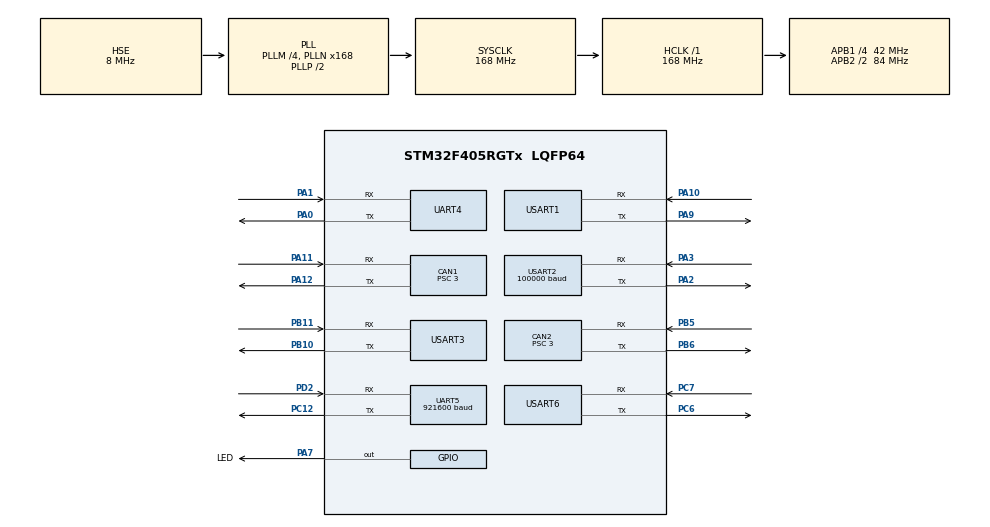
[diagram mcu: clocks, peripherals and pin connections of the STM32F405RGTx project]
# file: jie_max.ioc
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CAN1.ABOM=ENABLE
CAN1.BS1=CAN_BS1_6TQ
CAN1.BS2=CAN_BS2_7TQ
CAN1.CalculateBaudRate=1000000
CAN1.CalculateTimeBit=1000
CAN1.CalculateTimeQuantum=71.42857142857143
CAN1.NART=ENABLE
CAN1.Prescaler=3
CAN2.ABOM=ENABLE
CAN2.BS1=CAN_BS1_6TQ
CAN2.BS2=CAN_BS2_7TQ
CAN2.CalculateBaudRate=1000000
CAN2.CalculateTimeBit=1000
CAN2.CalculateTimeQuantum=71.42857142857143
CAN2.NART=ENABLE
CAN2.Prescaler=3
Dma.Request0=UART4_RX
Dma.Request1=UART4_TX
Dma.Request10=USART6_TX
Dma.Request2=USART3_RX
Dma.Request3=USART3_TX
Dma.Request4=USART2_RX
Dma.Request5=UART5_RX
Dma.Request6=UART5_TX
Dma.Request7=USART1_RX
Dma.Request8=USART1_TX
Dma.Request9=USART6_RX
Dma.UART4_RX.0.Direction=DMA_PERIPH_TO_MEMORY
Dma.UART4_RX.0.FIFOMode=DMA_FIFOMODE_DISABLE
Dma.UART4_RX.0.Instance=DMA1_Stream2
Dma.UART4_RX.0.MemDataAlignment=DMA_MDATAALIGN_BYTE
Dma.UART4_RX.0.MemInc=DMA_MINC_ENABLE
Dma.UART4_RX.0.Mode=DMA_CIRCULAR
Dma.UART4_RX.0.PeriphDataAlignment=DMA_PDATAALIGN_BYTE
Dma.UART4_RX.0.PeriphInc=DMA_PINC_DISABLE
Dma.UART4_RX.0.Priority=DMA_PRIORITY_LOW
Dma.UART4_TX.1.Direction=DMA_MEMORY_TO_PERIPH
Dma.UART4_TX.1.FIFOMode=DMA_FIFOMODE_DISABLE
Dma.UART4_TX.1.Instance=DMA1_Stream4
Dma.UART4_TX.1.MemDataAlignment=DMA_MDATAALIGN_BYTE
Dma.UART4_TX.1.MemInc=DMA_MINC_ENABLE
Dma.UART4_TX.1.Mode=DMA_NORMAL
Dma.UART4_TX.1.PeriphDataAlignment=DMA_PDATAALIGN_BYTE
Dma.UART4_TX.1.PeriphInc=DMA_PINC_DISABLE
Dma.UART4_TX.1.Priority=DMA_PRIORITY_LOW
Dma.UART5_RX.5.Direction=DMA_PERIPH_TO_MEMORY
Dma.UART5_RX.5.FIFOMode=DMA_FIFOMODE_DISABLE
Dma.UART5_RX.5.Instance=DMA1_Stream0
Dma.UART5_RX.5.MemDataAlignment=DMA_MDATAALIGN_BYTE
Dma.UART5_RX.5.MemInc=DMA_MINC_ENABLE
Dma.UART5_RX.5.Mode=DMA_CIRCULAR
Dma.UART5_RX.5.PeriphDataAlignment=DMA_PDATAALIGN_BYTE
Dma.UART5_RX.5.PeriphInc=DMA_PINC_DISABLE
Dma.UART5_RX.5.Priority=DMA_PRIORITY_HIGH
Dma.UART5_TX.6.Direction=DMA_MEMORY_TO_PERIPH
Dma.UART5_TX.6.FIFOMode=DMA_FIFOMODE_DISABLE
Dma.UART5_TX.6.Instance=DMA1_Stream7
Dma.UART5_TX.6.MemDataAlignment=DMA_MDATAALIGN_BYTE
Dma.UART5_TX.6.MemInc=DMA_MINC_ENABLE
Dma.UART5_TX.6.Mode=DMA_NORMAL
Dma.UART5_TX.6.PeriphDataAlignment=DMA_PDATAALIGN_BYTE
Dma.UART5_TX.6.PeriphInc=DMA_PINC_DISABLE
Dma.UART5_TX.6.Priority=DMA_PRIORITY_HIGH
Dma.USART1_RX.7.Direction=DMA_PERIPH_TO_MEMORY
Dma.USART1_RX.7.FIFOMode=DMA_FIFOMODE_DISABLE
Dma.USART1_RX.7.Instance=DMA2_Stream2
Dma.USART1_RX.7.MemDataAlignment=DMA_MDATAALIGN_BYTE
Dma.USART1_RX.7.MemInc=DMA_MINC_ENABLE
Dma.USART1_RX.7.Mode=DMA_CIRCULAR
Dma.USART1_RX.7.PeriphDataAlignment=DMA_PDATAALIGN_BYTE
Dma.USART1_RX.7.PeriphInc=DMA_PINC_DISABLE
Dma.USART1_RX.7.Priority=DMA_PRIORITY_LOW
Dma.USART1_TX.8.Direction=DMA_MEMORY_TO_PERIPH
Dma.USART1_TX.8.FIFOMode=DMA_FIFOMODE_DISABLE
Dma.USART1_TX.8.Instance=DMA2_Stream7
Dma.USART1_TX.8.MemDataAlignment=DMA_MDATAALIGN_BYTE
Dma.USART1_TX.8.MemInc=DMA_MINC_ENABLE
Dma.USART1_TX.8.Mode=DMA_NORMAL
Dma.USART1_TX.8.PeriphDataAlignment=DMA_PDATAALIGN_BYTE
Dma.USART1_TX.8.PeriphInc=DMA_PINC_DISABLE
Dma.USART1_TX.8.Priority=DMA_PRIORITY_LOW
Dma.USART2_RX.4.Direction=DMA_PERIPH_TO_MEMORY
Dma.USART2_RX.4.FIFOMode=DMA_FIFOMODE_DISABLE
Dma.USART2_RX.4.Instance=DMA1_Stream5
Dma.USART2_RX.4.MemDataAlignment=DMA_MDATAALIGN_BYTE
Dma.USART2_RX.4.MemInc=DMA_MINC_ENABLE
Dma.USART2_RX.4.Mode=DMA_CIRCULAR
Dma.USART2_RX.4.PeriphDataAlignment=DMA_PDATAALIGN_BYTE
Dma.USART2_RX.4.PeriphInc=DMA_PINC_DISABLE
Dma.USART2_RX.4.Priority=DMA_PRIORITY_LOW
Dma.USART3_RX.2.Direction=DMA_PERIPH_TO_MEMORY
Dma.USART3_RX.2.FIFOMode=DMA_FIFOMODE_DISABLE
Dma.USART3_RX.2.Instance=DMA1_Stream1
Dma.USART3_RX.2.MemDataAlignment=DMA_MDATAALIGN_BYTE
Dma.USART3_RX.2.MemInc=DMA_MINC_ENABLE
Dma.USART3_RX.2.Mode=DMA_NORMAL
Dma.USART3_RX.2.PeriphDataAlignment=DMA_PDATAALIGN_BYTE
Dma.USART3_RX.2.PeriphInc=DMA_PINC_DISABLE
Dma.USART3_RX.2.Priority=DMA_PRIORITY_LOW
Dma.USART3_TX.3.Direction=DMA_MEMORY_TO_PERIPH
Dma.USART3_TX.3.FIFOMode=DMA_FIFOMODE_DISABLE
Dma.USART3_TX.3.Instance=DMA1_Stream3
Dma.USART3_TX.3.MemDataAlignment=DMA_MDATAALIGN_BYTE
Dma.USART3_TX.3.MemInc=DMA_MINC_ENABLE
Dma.USART3_TX.3.Mode=DMA_NORMAL
Dma.USART3_TX.3.PeriphDataAlignment=DMA_PDATAALIGN_BYTE
Dma.USART3_TX.3.PeriphInc=DMA_PINC_DISABLE
Dma.USART3_TX.3.Priority=DMA_PRIORITY_LOW
Dma.USART6_RX.9.Direction=DMA_PERIPH_TO_MEMORY
Dma.USART6_RX.9.FIFOMode=DMA_FIFOMODE_DISABLE
Dma.USART6_RX.9.Instance=DMA2_Stream1
Dma.USART6_RX.9.MemDataAlignment=DMA_MDATAALIGN_BYTE
Dma.USART6_RX.9.MemInc=DMA_MINC_ENABLE
Dma.USART6_RX.9.Mode=DMA_CIRCULAR
Dma.USART6_RX.9.PeriphDataAlignment=DMA_PDATAALIGN_BYTE
Dma.USART6_RX.9.PeriphInc=DMA_PINC_DISABLE
Dma.USART6_RX.9.Priority=DMA_PRIORITY_LOW
Dma.USART6_TX.10.Direction=DMA_MEMORY_TO_PERIPH
Dma.USART6_TX.10.FIFOMode=DMA_FIFOMODE_DISABLE
Dma.USART6_TX.10.Instance=DMA2_Stream6
Dma.USART6_TX.10.MemDataAlignment=DMA_MDATAALIGN_BYTE
Dma.USART6_TX.10.MemInc=DMA_MINC_ENABLE
Dma.USART6_TX.10.Mode=DMA_NORMAL
Dma.USART6_TX.10.PeriphDataAlignment=DMA_PDATAALIGN_BYTE
Dma.USART6_TX.10.PeriphInc=DMA_PINC_DISABLE
Dma.USART6_TX.10.Priority=DMA_PRIORITY_LOW
FREERTOS.Tasks01=defaultTask,24,128,StartDefaultTask,Default,NULL,Dynamic,NULL,NULL;dr16,40,128,dr16_task,As weak,NULL,Dynamic,NULL,NULL;vt13,40,128,vt13_task,As weak,NULL,Dynamic,NULL,NULL;vofa,8,256,vofa_task,As weak,NULL,Dynamic,NULL,NULL;imu_can,40,128,imu_can_task,As weak,NULL,Dynamic,NULL,NULL;lx824,8,256,lx824_task,As weak,NULL,Dynamic,NULL,NULL;I6X,40,128,I6X_task,As weak,NULL,Dynamic,NULL,NULL;imu_485,40,128,imu_485_task,As weak,NULL,Dynamic,NULL,NULL;gimbal,24,512,gimbal_task,As weak,NULL,Dynamic,NULL,NULL;chassis,8,256,chassis_task,As weak,NULL,Dynamic,NULL,NULL;joint,24,256,joint_task,As weak,NULL,Dynamic,NULL,NULL
FREERTOS.configCHECK_FOR_STACK_OVERFLOW=2
FREERTOS.configENABLE_FPU=1
FREERTOS.configGENERATE_RUN_TIME_STATS=1
FREERTOS.configRECORD_STACK_HIGH_ADDRESS=1
FREERTOS.configUSE_MALLOC_FAILED_HOOK=1
Mcu.Family=STM32F4
Mcu.Name=STM32F405RGTx
Mcu.Package=LQFP64
NVIC.CAN1_RX0_IRQn=true\:5\:0\:false\:false\:true\:true\:true\:true\:true
NVIC.CAN1_RX1_IRQn=true\:5\:0\:false\:false\:true\:true\:true\:true\:true
NVIC.CAN1_TX_IRQn=true\:5\:0\:false\:false\:true\:true\:true\:true\:true
NVIC.CAN2_RX0_IRQn=true\:5\:0\:false\:false\:true\:true\:true\:true\:true
NVIC.CAN2_RX1_IRQn=true\:5\:0\:false\:false\:true\:true\:true\:true\:true
NVIC.CAN2_TX_IRQn=true\:5\:0\:false\:false\:true\:true\:true\:true\:true
NVIC.DMA1_Stream0_IRQn=true\:5\:0\:false\:false\:true\:true\:false\:true\:true
NVIC.DMA1_Stream1_IRQn=true\:5\:0\:false\:false\:true\:true\:false\:true\:true
NVIC.DMA1_Stream2_IRQn=true\:5\:0\:false\:false\:true\:true\:false\:true\:true
NVIC.DMA1_Stream3_IRQn=true\:5\:0\:false\:false\:true\:true\:false\:true\:true
NVIC.DMA1_Stream4_IRQn=true\:5\:0\:false\:false\:true\:true\:false\:true\:true
NVIC.DMA1_Stream5_IRQn=true\:5\:0\:false\:false\:true\:true\:false\:true\:true
NVIC.DMA1_Stream7_IRQn=true\:5\:0\:false\:false\:true\:true\:false\:true\:true
NVIC.DMA2_Stream1_IRQn=true\:5\:0\:false\:false\:true\:true\:false\:true\:true
NVIC.DMA2_Stream2_IRQn=true\:5\:0\:false\:false\:true\:true\:false\:true\:true
NVIC.DMA2_Stream6_IRQn=true\:5\:0\:false\:false\:true\:true\:false\:true\:true
NVIC.DMA2_Stream7_IRQn=true\:5\:0\:false\:false\:true\:true\:false\:true\:true
NVIC.PriorityGroup=NVIC_PRIORITYGROUP_4
NVIC.TIM1_UP_TIM10_IRQn=true\:5\:0\:false\:false\:true\:true\:true\:true\:true
NVIC.TIM7_IRQn=true\:15\:0\:false\:false\:true\:false\:false\:true\:true
NVIC.TimeBase=TIM7_IRQn
NVIC.TimeBaseIP=TIM7
NVIC.UART4_IRQn=true\:5\:0\:false\:false\:true\:true\:false\:true\:true
NVIC.UART5_IRQn=true\:5\:0\:false\:false\:true\:true\:true\:true\:true
NVIC.USART1_IRQn=true\:5\:0\:false\:false\:true\:true\:true\:true\:true
NVIC.USART2_IRQn=true\:5\:0\:false\:false\:true\:true\:true\:true\:true
NVIC.USART3_IRQn=true\:5\:0\:false\:false\:true\:true\:true\:true\:true
NVIC.USART6_IRQn=true\:5\:0\:false\:false\:true\:true\:true\:true\:true
PA0-WKUP.Mode=Asynchronous
PA0-WKUP.Signal=UART4_TX
PA1.Mode=Asynchronous
PA1.Signal=UART4_RX
PA10.Mode=Asynchronous
PA10.Signal=USART1_RX
PA11.Mode=CAN_Activate
PA11.Signal=CAN1_RX
PA12.Mode=CAN_Activate
PA12.Signal=CAN1_TX
PA13.Mode=Serial_Wire
PA13.Signal=SYS_JTMS-SWDIO
PA14.Mode=Serial_Wire
PA14.Signal=SYS_JTCK-SWCLK
PA2.Mode=Asynchronous
PA2.Signal=USART2_TX
PA3.Mode=Asynchronous
PA3.Signal=USART2_RX
PA7.GPIO_Label=LED
PA7.Signal=GPIO_Output
PA9.Mode=Asynchronous
PA9.Signal=USART1_TX
PB10.Mode=Asynchronous
PB10.Signal=USART3_TX
PB11.Mode=Asynchronous
PB11.Signal=USART3_RX
PB5.Mode=CAN_Activate
PB5.Signal=CAN2_RX
PB6.Mode=CAN_Activate
PB6.Signal=CAN2_TX
PC12.Mode=Asynchronous
PC12.Signal=UART5_TX
PC6.Mode=Asynchronous
PC6.Signal=USART6_TX
PC7.Mode=Asynchronous
PC7.Signal=USART6_RX
PD2.Mode=Asynchronous
PD2.Signal=UART5_RX
PH0-OSC_IN.Mode=HSE-External-Oscillator
PH0-OSC_IN.Signal=RCC_OSC_IN
PH1-OSC_OUT.Mode=HSE-External-Oscillator
PH1-OSC_OUT.Signal=RCC_OSC_OUT
ProjectManager.HeapSize=0x200
ProjectManager.StackSize=0x400
ProjectManager.TargetToolchain=CMake
RCC.48MHZClocksFreq_Value=56000000
RCC.AHBFreq_Value=168000000
RCC.APB1CLKDivider=RCC_HCLK_DIV4
RCC.APB1Freq_Value=42000000
RCC.APB1TimFreq_Value=84000000
RCC.APB2CLKDivider=RCC_HCLK_DIV2
RCC.APB2Freq_Value=84000000
RCC.APB2TimFreq_Value=168000000
RCC.CortexFreq_Value=168000000
RCC.HCLKFreq_Value=168000000
RCC.HSE_VALUE=8000000
RCC.HSI_VALUE=16000000
RCC.LSE_VALUE=32768
RCC.PLLM=4
RCC.PLLN=168
RCC.PLLQ=6
RCC.PLLSourceVirtual=RCC_PLLSOURCE_HSE
RCC.SYSCLKFreq_VALUE=168000000
RCC.SYSCLKSource=RCC_SYSCLKSOURCE_PLLCLK
RCC.VCOOutputFreq_Value=336000000
STMicroelectronics.X-CUBE-ALGOBUILD.1.5.0.LibraryCcDSPOoLibraryJjDSPOoLibrary=true
TIM10.Period=1000
TIM10.Prescaler=168-1
UART4.VirtualMode=Asynchronous
UART5.BaudRate=921600
UART5.VirtualMode=Asynchronous
USART1.VirtualMode=VM_ASYNC
USART2.BaudRate=100000
USART2.Mode=MODE_RX
USART2.Parity=PARITY_EVEN
USART2.VirtualMode=VM_ASYNC
USART2.WordLength=WORDLENGTH_9B
USART3.VirtualMode=VM_ASYNC
USART6.VirtualMode=VM_ASYNC
VP_FREERTOS_VS_CMSIS_V2.Mode=CMSIS_V2
VP_STMicroelectronics.X-CUBE-ALGOBUILD_VS_DSPOoLibraryJjLibrary_1.5.0_1.5.0.Mode=DSPOoLibraryJjLibrary
VP_SYS_VS_tim7.Mode=TIM7
VP_TIM10_VS_ClockSourceINT.Mode=Enable_Timer
board=custom

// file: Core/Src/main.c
/* USER CODE BEGIN Header */
/**
 ******************************************************************************
 * @file           : main.c
 * @brief          : Main program body
 ******************************************************************************
 * @attention
 *
 * Copyright (c) 2026 STMicroelectronics.
 * All rights reserved.
 *
 * This software is licensed under terms that can be found in the LICENSE file
 * in the root directory of this software component.
 * If no LICENSE file comes with this software, it is provided AS-IS.
 *
 ******************************************************************************
 */
/* USER CODE END Header */
#include "main.h"
#include "can.h"
#include "cmsis_os.h"
#include "dma.h"
#include "gpio.h"
#include "tim.h"
#include "usart.h"

/* USER CODE BEGIN Includes */
#include "bsp_dwt.h"
#include "can_device.h"

/* USER CODE END Includes */

/* USER CODE BEGIN PV */
/* CAN 控制块、IMU 对象与总线初始化均封装在 app/can_device 中。 */
/* USER CODE END PV */

void SystemClock_Config(void);
void MX_FREERTOS_Init(void);

int main(void) {

  /* MCU Configuration--------------------------------------------------------*/

  /* Reset of all peripherals, Initializes the Flash interface and the Systick.
   */
  HAL_Init();

  /* Configure the system clock */
  SystemClock_Config();

  /* Initialize all configured peripherals */
  MX_GPIO_Init();
  MX_DMA_Init();
  MX_CAN1_Init();
  MX_CAN2_Init();
  MX_UART4_Init();
  MX_USART3_UART_Init();
  MX_USART2_UART_Init();
  MX_UART5_Init();
  MX_USART1_UART_Init();
  MX_USART6_UART_Init();
  MX_TIM10_Init();
  /* USER CODE BEGIN 2 */
  /* CAN 对象绑定、过滤器配置、设备注册与总线启动集中在 can_device。 */
  can_device_Init();
  DWT_Init(168);
  /* USER CODE END 2 */

  /* Init scheduler */
  osKernelInitialize(); /* Call init function for freertos objects (in
                           cmsis_os2.c) */
  MX_FREERTOS_Init();

  /* Start scheduler */
  osKernelStart();

  /* We should never get here as control is now taken by the scheduler */

  /* Infinite loop */
  while (1) {

  }
}

void SystemClock_Config(void) {
  RCC_OscInitTypeDef RCC_OscInitStruct = {0};
  RCC_ClkInitTypeDef RCC_ClkInitStruct = {0};

  /** Configure the main internal regulator output voltage
   */
  __HAL_RCC_PWR_CLK_ENABLE();
  __HAL_PWR_VOLTAGESCALING_CONFIG(PWR_REGULATOR_VOLTAGE_SCALE1);

  /** Initializes the RCC Oscillators according to the specified parameters
   * in the RCC_OscInitTypeDef structure.
   */
  RCC_OscInitStruct.OscillatorType = RCC_OSCILLATORTYPE_HSE;
  RCC_OscInitStruct.HSEState = RCC_HSE_ON;
  RCC_OscInitStruct.PLL.PLLState = RCC_PLL_ON;
  RCC_OscInitStruct.PLL.PLLSource = RCC_PLLSOURCE_HSE;
  RCC_OscInitStruct.PLL.PLLM = 4;
  RCC_OscInitStruct.PLL.PLLN = 168;
  RCC_OscInitStruct.PLL.PLLP = RCC_PLLP_DIV2;
  RCC_OscInitStruct.PLL.PLLQ = 6;
  if (HAL_RCC_OscConfig(&RCC_OscInitStruct) != HAL_OK) {
    Error_Handler();
  }

  /** Initializes the CPU, AHB and APB buses clocks
   */
  RCC_ClkInitStruct.ClockType = RCC_CLOCKTYPE_HCLK | RCC_CLOCKTYPE_SYSCLK |
                                RCC_CLOCKTYPE_PCLK1 | RCC_CLOCKTYPE_PCLK2;
  RCC_ClkInitStruct.SYSCLKSource = RCC_SYSCLKSOURCE_PLLCLK;
  RCC_ClkInitStruct.AHBCLKDivider = RCC_SYSCLK_DIV1;
  RCC_ClkInitStruct.APB1CLKDivider = RCC_HCLK_DIV4;
  RCC_ClkInitStruct.APB2CLKDivider = RCC_HCLK_DIV2;

  if (HAL_RCC_ClockConfig(&RCC_ClkInitStruct, FLASH_LATENCY_5) != HAL_OK) {
    Error_Handler();
  }
}

void HAL_TIM_PeriodElapsedCallback(TIM_HandleTypeDef *htim) {
  if (htim->Instance == TIM7) {
    HAL_IncTick();
  }
}

void Error_Handler(void) {
  __disable_irq();
  while (1) {
  }
}
#ifdef USE_FULL_ASSERT
/**
 * @brief  Reports the name of the source file and the source line number
 *         where the assert_param error has occurred.
 * @param  file: pointer to the source file name
 * @param  line: assert_param error line source number
 * @retval None
 */
void assert_failed(uint8_t *file, uint32_t line) {
  /* USER CODE BEGIN 6 */
  /* User can add his own implementation to report the file name and line
     number, ex: printf("Wrong parameters value: file %s on line %d\r\n", file,
     line) */
  /* USER CODE END 6 */
}
#endif /* USE_FULL_ASSERT */

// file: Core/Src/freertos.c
/* USER CODE BEGIN Header */
/**
  ******************************************************************************
  * File Name          : freertos.c
  * Description        : Code for freertos applications
  ******************************************************************************
  * @attention
  *
  * Copyright (c) 2026 STMicroelectronics.
  * All rights reserved.
  *
  * This software is licensed under terms that can be found in the LICENSE file
  * in the root directory of this software component.
  * If no LICENSE file comes with this software, it is provided AS-IS.
  *
  ******************************************************************************
  */
/* USER CODE END Header */

#include "FreeRTOS.h"
#include "task.h"
#include "main.h"
#include "cmsis_os.h"

/* Definitions for defaultTask */
osThreadId_t defaultTaskHandle;
const osThreadAttr_t defaultTask_attributes = {
  .name = "defaultTask",
  .stack_size = 128 * 4,
  .priority = (osPriority_t) osPriorityNormal,
};
/* Definitions for dr16 */
osThreadId_t dr16Handle;
const osThreadAttr_t dr16_attributes = {
  .name = "dr16",
  .stack_size = 128 * 4,
  .priority = (osPriority_t) osPriorityHigh,
};
/* Definitions for vt13 */
osThreadId_t vt13Handle;
const osThreadAttr_t vt13_attributes = {
  .name = "vt13",
  .stack_size = 128 * 4,
  .priority = (osPriority_t) osPriorityHigh,
};
/* Definitions for vofa */
osThreadId_t vofaHandle;
const osThreadAttr_t vofa_attributes = {
  .name = "vofa",
  .stack_size = 256 * 4,
  .priority = (osPriority_t) osPriorityLow,
};
/* Definitions for imu_can */
osThreadId_t imu_canHandle;
const osThreadAttr_t imu_can_attributes = {
  .name = "imu_can",
  .stack_size = 128 * 4,
  .priority = (osPriority_t) osPriorityHigh,
};
/* Definitions for lx824 */
osThreadId_t lx824Handle;
const osThreadAttr_t lx824_attributes = {
  .name = "lx824",
  .stack_size = 256 * 4,
  .priority = (osPriority_t) osPriorityLow,
};
/* Definitions for I6X */
osThreadId_t I6XHandle;
const osThreadAttr_t I6X_attributes = {
  .name = "I6X",
  .stack_size = 128 * 4,
  .priority = (osPriority_t) osPriorityHigh,
};
/* Definitions for imu_485 */
osThreadId_t imu_485Handle;
const osThreadAttr_t imu_485_attributes = {
  .name = "imu_485",
  .stack_size = 128 * 4,
  .priority = (osPriority_t) osPriorityHigh,
};
/* Definitions for gimbal */
osThreadId_t gimbalHandle;
const osThreadAttr_t gimbal_attributes = {
  .name = "gimbal",
  .stack_size = 512 * 4,
  .priority = (osPriority_t) osPriorityNormal,
};
/* Definitions for chassis */
osThreadId_t chassisHandle;
const osThreadAttr_t chassis_attributes = {
  .name = "chassis",
  .stack_size = 256 * 4,
  .priority = (osPriority_t) osPriorityLow,
};
/* Definitions for joint */
osThreadId_t jointHandle;
const osThreadAttr_t joint_attributes = {
  .name = "joint",
  .stack_size = 256 * 4,
  .priority = (osPriority_t) osPriorityNormal,
};

void StartDefaultTask(void *argument);
void dr16_task(void *argument);
void vt13_task(void *argument);
void vofa_task(void *argument);
void imu_can_task(void *argument);
void lx824_task(void *argument);
void I6X_task(void *argument);
void imu_485_task(void *argument);
void gimbal_task(void *argument);
void chassis_task(void *argument);
void joint_task(void *argument);

void MX_FREERTOS_Init(void); /* (MISRA C 2004 rule 8.1) */

/* Hook prototypes */
void configureTimerForRunTimeStats(void);
unsigned long getRunTimeCounterValue(void);
void vApplicationStackOverflowHook(xTaskHandle xTask, signed char *pcTaskName);
void vApplicationMallocFailedHook(void);

/* USER CODE BEGIN 1 */
/* Functions needed when configGENERATE_RUN_TIME_STATS is on */
__weak void configureTimerForRunTimeStats(void)
{

}

__weak unsigned long getRunTimeCounterValue(void)
{
return 0;
}
/* USER CODE END 1 */

/* USER CODE BEGIN 4 */
// 栈溢出钩子函数
void vApplicationStackOverflowHook(xTaskHandle xTask, signed char *pcTaskName)
{
  (void)xTask;
  (void)pcTaskName;
  taskDISABLE_INTERRUPTS();
  for (;;) {
  }
}
/* USER CODE END 4 */

/* USER CODE BEGIN 5 */
// 内存分配失败钩子函数
void vApplicationMallocFailedHook(void)
{
  taskDISABLE_INTERRUPTS();
  for (;;)
  {
  }
}
/* USER CODE END 5 */

void MX_FREERTOS_Init(void) {

  /* Create the thread(s) */
  /* creation of defaultTask */
  defaultTaskHandle = osThreadNew(StartDefaultTask, NULL, &defaultTask_attributes);

  /* creation of dr16 */
  dr16Handle = osThreadNew(dr16_task, NULL, &dr16_attributes);

  /* creation of vt13 */
  vt13Handle = osThreadNew(vt13_task, NULL, &vt13_attributes);

  /* creation of vofa */
  vofaHandle = osThreadNew(vofa_task, NULL, &vofa_attributes);

  /* creation of imu_can */
  imu_canHandle = osThreadNew(imu_can_task, NULL, &imu_can_attributes);

  /* creation of lx824 */
  lx824Handle = osThreadNew(lx824_task, NULL, &lx824_attributes);

  /* creation of I6X */
  I6XHandle = osThreadNew(I6X_task, NULL, &I6X_attributes);

  /* creation of imu_485 */
  imu_485Handle = osThreadNew(imu_485_task, NULL, &imu_485_attributes);

  /* creation of gimbal */
  gimbalHandle = osThreadNew(gimbal_task, NULL, &gimbal_attributes);

  /* creation of chassis */
  chassisHandle = osThreadNew(chassis_task, NULL, &chassis_attributes);

  /* creation of joint */
  jointHandle = osThreadNew(joint_task, NULL, &joint_attributes);

}

void StartDefaultTask(void *argument)
{
  for(;;)
  {
    osDelay(1);
  }
}

__weak void dr16_task(void *argument)
{
  for(;;)
  {
    osDelay(1);
  }
}

__weak void vt13_task(void *argument)
{
  for(;;)
  {
    osDelay(1);
  }
}

__weak void vofa_task(void *argument)
{
  for(;;)
  {
    osDelay(1);
  }
}

__weak void imu_can_task(void *argument)
{
  for(;;)
  {
    osDelay(1);
  }
}

__weak void lx824_task(void *argument)
{
  for(;;)
  {
    osDelay(1);
  }
}

__weak void I6X_task(void *argument)
{
  for(;;)
  {
    osDelay(1);
  }
}

__weak void imu_485_task(void *argument)
{
  for(;;)
  {
    osDelay(1);
  }
}

__weak void gimbal_task(void *argument)
{
  for(;;)
  {
    osDelay(1);
  }
}

__weak void chassis_task(void *argument)
{
  for(;;)
  {
    osDelay(1);
  }
}

__weak void joint_task(void *argument)
{
  for(;;)
  {
    osDelay(1);
  }
}
